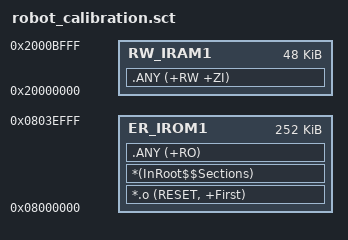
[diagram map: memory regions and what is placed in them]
; 程序及只读数据限制在前252KB，最后4KB分别留给停稳位置日志和电机校准记录。
LR_IROM1 0x08000000 0x0003F000 {
  ER_IROM1 0x08000000 0x0003F000 {
    *.o (RESET, +First)
    *(InRoot$$Sections)
    .ANY (+RO)
  }
  ; 使用工程原有48KB RAM配置。
  RW_IRAM1 0x20000000 0x0000C000 {
    .ANY (+RW +ZI)
  }
}
